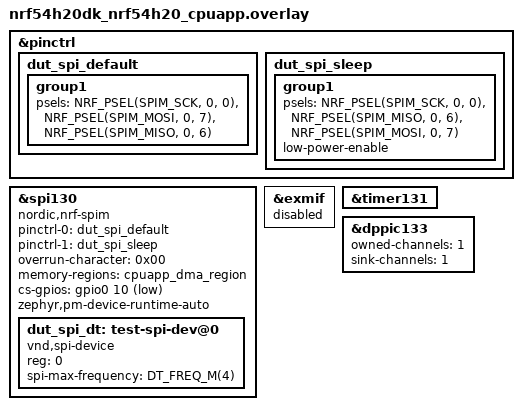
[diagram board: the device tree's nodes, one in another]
/*
 * Copyright (c) 2025 Nordic Semiconductor ASA
 *
 * SPDX-License-Identifier: LicenseRef-Nordic-5-Clause
 */

/* Required loopbacks:
 * P0.07 <-> P0.06
 */

&pinctrl {
	dut_spi_default: dut_spi_default {
		group1 {
			psels = <NRF_PSEL(SPIM_SCK, 0, 0)>,
				<NRF_PSEL(SPIM_MOSI, 0, 7)>,
				<NRF_PSEL(SPIM_MISO, 0, 6)>;
		};
	};

	dut_spi_sleep: dut_spi_sleep {
		group1 {
			psels = <NRF_PSEL(SPIM_SCK, 0, 0)>,
				<NRF_PSEL(SPIM_MISO, 0, 6)>,
				<NRF_PSEL(SPIM_MOSI, 0, 7)>;
			low-power-enable;
		};
	};
};

dut_spi: &spi130 {
	compatible = "nordic,nrf-spim";
	status = "okay";
	pinctrl-0 = <&dut_spi_default>;
	pinctrl-1 = <&dut_spi_sleep>;
	pinctrl-names = "default", "sleep";
	overrun-character = <0x00>;
	memory-regions = <&cpuapp_dma_region>;
	cs-gpios = <&gpio0 10 GPIO_ACTIVE_LOW>;
	zephyr,pm-device-runtime-auto;

	dut_spi_dt: test-spi-dev@0 {
		compatible = "vnd,spi-device";
		reg = <0>;
		spi-max-frequency = <DT_FREQ_M(4)>;
	};
};

&exmif {
	status = "disabled";
};

tst_timer: &timer131 {
	status = "okay";
};

&dppic133 {
	owned-channels = <1>;
	sink-channels = <1>;
	status = "okay";
};
